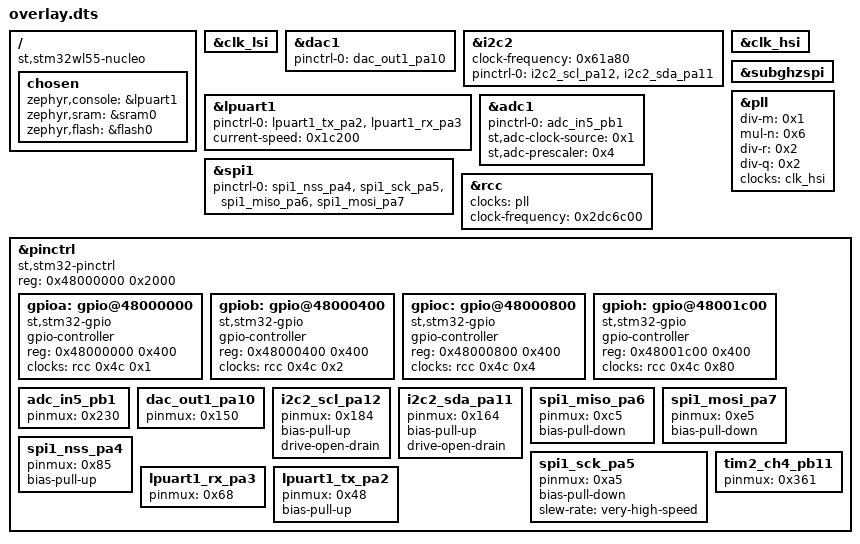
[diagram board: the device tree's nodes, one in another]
/ {
	compatible = "st,stm32wl55-nucleo";
	chosen {
		zephyr,console = &lpuart1;
		zephyr,sram = &sram0;
		zephyr,flash = &flash0;
	};
};
&clk_lsi{
	status = "okay";
};
&dac1{
	status = "okay";
	pinctrl-0 = < &dac_out1_pa10 >;
	pinctrl-names = "default";
};
&i2c2{
	clock-frequency = < 0x61a80 >;
	status = "okay";
	pinctrl-0 = < &i2c2_scl_pa12 &i2c2_sda_pa11 >;
	pinctrl-names = "default";
};
&clk_hsi{
	status = "okay";
};
&lpuart1{
	status = "okay";
	pinctrl-0 = < &lpuart1_tx_pa2 &lpuart1_rx_pa3 >;
	pinctrl-names = "default";
	current-speed = < 0x1c200 >;
};
&adc1{
	status = "okay";
	pinctrl-0 = < &adc_in5_pb1 >;
	pinctrl-names = "default";
	st,adc-clock-source = < 0x1 >;
	st,adc-prescaler = < 0x4 >;
};
&subghzspi{
	status = "okay";
};
&spi1{
	status = "okay";
	pinctrl-0 = < &spi1_nss_pa4 &spi1_sck_pa5 &spi1_miso_pa6 &spi1_mosi_pa7 >;
	pinctrl-names = "default";
};
&pll{
	status = "okay";
	div-m = < 0x1 >;
	mul-n = < 0x6 >;
	div-r = < 0x2 >;
	div-q = < 0x2 >;
	clocks = < &clk_hsi >;
};
&rcc{
	clocks = < &pll >;
	clock-frequency = < 0x2dc6c00 >;
};
&pinctrl{
	compatible = "st,stm32-pinctrl";
	#address-cells = < 0x1 >;
	#size-cells = < 0x1 >;
	reg = < 0x48000000 0x2000 >;
	gpioa: gpio@48000000 {
		compatible = "st,stm32-gpio";
		gpio-controller;
		#gpio-cells = < 0x2 >;
		reg = < 0x48000000 0x400 >;
		clocks = < &rcc 0x4c 0x1 >;
	};
	gpiob: gpio@48000400 {
		compatible = "st,stm32-gpio";
		gpio-controller;
		#gpio-cells = < 0x2 >;
		reg = < 0x48000400 0x400 >;
		clocks = < &rcc 0x4c 0x2 >;
	};
	gpioc: gpio@48000800 {
		compatible = "st,stm32-gpio";
		gpio-controller;
		#gpio-cells = < 0x2 >;
		reg = < 0x48000800 0x400 >;
		clocks = < &rcc 0x4c 0x4 >;
	};
	gpioh: gpio@48001c00 {
		compatible = "st,stm32-gpio";
		gpio-controller;
		#gpio-cells = < 0x2 >;
		reg = < 0x48001c00 0x400 >;
		clocks = < &rcc 0x4c 0x80 >;
	};
	adc_in5_pb1: adc_in5_pb1 {
		pinmux = < 0x230 >;
	};
	dac_out1_pa10: dac_out1_pa10 {
		pinmux = < 0x150 >;
	};
	i2c2_scl_pa12: i2c2_scl_pa12 {
		pinmux = < 0x184 >;
		bias-pull-up;
		drive-open-drain;
	};
	i2c2_sda_pa11: i2c2_sda_pa11 {
		pinmux = < 0x164 >;
		bias-pull-up;
		drive-open-drain;
	};
	spi1_miso_pa6: spi1_miso_pa6 {
		pinmux = < 0xc5 >;
		bias-pull-down;
	};
	spi1_mosi_pa7: spi1_mosi_pa7 {
		pinmux = < 0xe5 >;
		bias-pull-down;
	};
	spi1_nss_pa4: spi1_nss_pa4 {
		pinmux = < 0x85 >;
		bias-pull-up;
	};
	spi1_sck_pa5: spi1_sck_pa5 {
		pinmux = < 0xa5 >;
		bias-pull-down;
		slew-rate = "very-high-speed";
	};
	tim2_ch4_pb11: tim2_ch4_pb11 {
		pinmux = < 0x361 >;
	};
	lpuart1_rx_pa3: lpuart1_rx_pa3 {
		pinmux = < 0x68 >;
	};
	lpuart1_tx_pa2: lpuart1_tx_pa2 {
		pinmux = < 0x48 >;
		bias-pull-up;
	};
};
